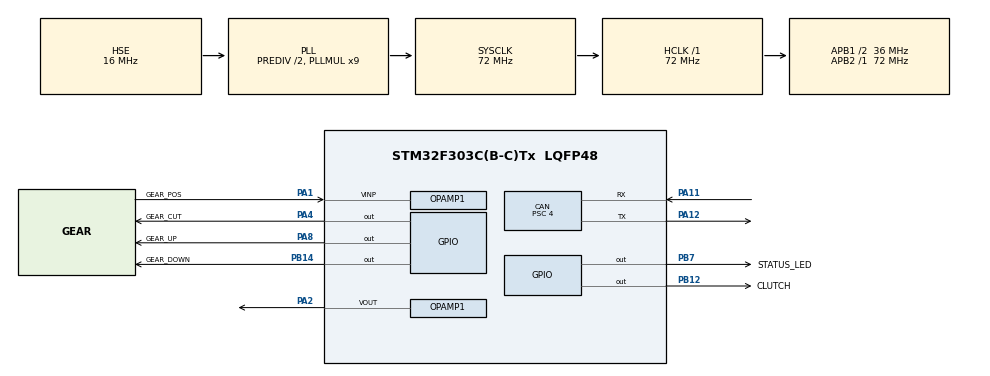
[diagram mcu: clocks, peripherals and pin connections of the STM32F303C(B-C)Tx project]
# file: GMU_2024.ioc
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ADC1.Channel-1\#ChannelRegularConversion=ADC_CHANNEL_3
ADC1.Channel-10\#ChannelRegularConversion=ADC_CHANNEL_3
ADC1.Channel-11\#ChannelRegularConversion=ADC_CHANNEL_3
ADC1.Channel-12\#ChannelRegularConversion=ADC_CHANNEL_3
ADC1.Channel-13\#ChannelRegularConversion=ADC_CHANNEL_3
ADC1.Channel-14\#ChannelRegularConversion=ADC_CHANNEL_3
ADC1.Channel-15\#ChannelRegularConversion=ADC_CHANNEL_3
ADC1.Channel-16\#ChannelRegularConversion=ADC_CHANNEL_3
ADC1.Channel-2\#ChannelRegularConversion=ADC_CHANNEL_3
ADC1.Channel-3\#ChannelRegularConversion=ADC_CHANNEL_3
ADC1.Channel-4\#ChannelRegularConversion=ADC_CHANNEL_3
ADC1.Channel-5\#ChannelRegularConversion=ADC_CHANNEL_3
ADC1.Channel-6\#ChannelRegularConversion=ADC_CHANNEL_3
ADC1.Channel-7\#ChannelRegularConversion=ADC_CHANNEL_3
ADC1.Channel-8\#ChannelRegularConversion=ADC_CHANNEL_3
ADC1.Channel-9\#ChannelRegularConversion=ADC_CHANNEL_3
ADC1.ClockPrescaler=ADC_CLOCK_SYNC_PCLK_DIV1
ADC1.ContinuousConvMode=ENABLE
ADC1.DMAContinuousRequests=ENABLE
ADC1.EnableInjectedConversion=DISABLE
ADC1.NbrOfConversion=16
ADC1.NbrOfConversionFlag=1
ADC1.Offset-1\#ChannelRegularConversion=0
ADC1.Offset-10\#ChannelRegularConversion=0
ADC1.Offset-11\#ChannelRegularConversion=0
ADC1.Offset-12\#ChannelRegularConversion=0
ADC1.Offset-13\#ChannelRegularConversion=0
ADC1.Offset-14\#ChannelRegularConversion=0
ADC1.Offset-15\#ChannelRegularConversion=0
ADC1.Offset-16\#ChannelRegularConversion=0
ADC1.Offset-2\#ChannelRegularConversion=0
ADC1.Offset-3\#ChannelRegularConversion=0
ADC1.Offset-4\#ChannelRegularConversion=0
ADC1.Offset-5\#ChannelRegularConversion=0
ADC1.Offset-6\#ChannelRegularConversion=0
ADC1.Offset-7\#ChannelRegularConversion=0
ADC1.Offset-8\#ChannelRegularConversion=0
ADC1.Offset-9\#ChannelRegularConversion=0
ADC1.OffsetNumber-1\#ChannelRegularConversion=ADC_OFFSET_NONE
ADC1.OffsetNumber-10\#ChannelRegularConversion=ADC_OFFSET_NONE
ADC1.OffsetNumber-11\#ChannelRegularConversion=ADC_OFFSET_NONE
ADC1.OffsetNumber-12\#ChannelRegularConversion=ADC_OFFSET_NONE
ADC1.OffsetNumber-13\#ChannelRegularConversion=ADC_OFFSET_NONE
ADC1.OffsetNumber-14\#ChannelRegularConversion=ADC_OFFSET_NONE
ADC1.OffsetNumber-15\#ChannelRegularConversion=ADC_OFFSET_NONE
ADC1.OffsetNumber-16\#ChannelRegularConversion=ADC_OFFSET_NONE
ADC1.OffsetNumber-2\#ChannelRegularConversion=ADC_OFFSET_NONE
ADC1.OffsetNumber-3\#ChannelRegularConversion=ADC_OFFSET_NONE
ADC1.OffsetNumber-4\#ChannelRegularConversion=ADC_OFFSET_NONE
ADC1.OffsetNumber-5\#ChannelRegularConversion=ADC_OFFSET_NONE
ADC1.OffsetNumber-6\#ChannelRegularConversion=ADC_OFFSET_NONE
ADC1.OffsetNumber-7\#ChannelRegularConversion=ADC_OFFSET_NONE
ADC1.OffsetNumber-8\#ChannelRegularConversion=ADC_OFFSET_NONE
ADC1.OffsetNumber-9\#ChannelRegularConversion=ADC_OFFSET_NONE
ADC1.Rank-1\#ChannelRegularConversion=1
ADC1.Rank-10\#ChannelRegularConversion=10
ADC1.Rank-11\#ChannelRegularConversion=11
ADC1.Rank-12\#ChannelRegularConversion=12
ADC1.Rank-13\#ChannelRegularConversion=13
ADC1.Rank-14\#ChannelRegularConversion=14
ADC1.Rank-15\#ChannelRegularConversion=15
ADC1.Rank-16\#ChannelRegularConversion=16
ADC1.Rank-2\#ChannelRegularConversion=2
ADC1.Rank-3\#ChannelRegularConversion=3
ADC1.Rank-4\#ChannelRegularConversion=4
ADC1.Rank-5\#ChannelRegularConversion=5
ADC1.Rank-6\#ChannelRegularConversion=6
ADC1.Rank-7\#ChannelRegularConversion=7
ADC1.Rank-8\#ChannelRegularConversion=8
ADC1.Rank-9\#ChannelRegularConversion=9
ADC1.SamplingTime-1\#ChannelRegularConversion=ADC_SAMPLETIME_61CYCLES_5
ADC1.SamplingTime-10\#ChannelRegularConversion=ADC_SAMPLETIME_61CYCLES_5
ADC1.SamplingTime-11\#ChannelRegularConversion=ADC_SAMPLETIME_61CYCLES_5
ADC1.SamplingTime-12\#ChannelRegularConversion=ADC_SAMPLETIME_61CYCLES_5
ADC1.SamplingTime-13\#ChannelRegularConversion=ADC_SAMPLETIME_61CYCLES_5
ADC1.SamplingTime-14\#ChannelRegularConversion=ADC_SAMPLETIME_61CYCLES_5
ADC1.SamplingTime-15\#ChannelRegularConversion=ADC_SAMPLETIME_61CYCLES_5
ADC1.SamplingTime-16\#ChannelRegularConversion=ADC_SAMPLETIME_61CYCLES_5
ADC1.SamplingTime-2\#ChannelRegularConversion=ADC_SAMPLETIME_61CYCLES_5
ADC1.SamplingTime-3\#ChannelRegularConversion=ADC_SAMPLETIME_61CYCLES_5
ADC1.SamplingTime-4\#ChannelRegularConversion=ADC_SAMPLETIME_61CYCLES_5
ADC1.SamplingTime-5\#ChannelRegularConversion=ADC_SAMPLETIME_61CYCLES_5
ADC1.SamplingTime-6\#ChannelRegularConversion=ADC_SAMPLETIME_61CYCLES_5
ADC1.SamplingTime-7\#ChannelRegularConversion=ADC_SAMPLETIME_61CYCLES_5
ADC1.SamplingTime-8\#ChannelRegularConversion=ADC_SAMPLETIME_61CYCLES_5
ADC1.SamplingTime-9\#ChannelRegularConversion=ADC_SAMPLETIME_61CYCLES_5
ADC1.SamplingTimeOPAMP-1\#ChannelRegularConversion=ADC_SAMPLETIME_61CYCLES_5
ADC1.SamplingTimeOPAMP-10\#ChannelRegularConversion=ADC_SAMPLETIME_61CYCLES_5
ADC1.SamplingTimeOPAMP-11\#ChannelRegularConversion=ADC_SAMPLETIME_61CYCLES_5
ADC1.SamplingTimeOPAMP-12\#ChannelRegularConversion=ADC_SAMPLETIME_61CYCLES_5
ADC1.SamplingTimeOPAMP-13\#ChannelRegularConversion=ADC_SAMPLETIME_61CYCLES_5
ADC1.SamplingTimeOPAMP-14\#ChannelRegularConversion=ADC_SAMPLETIME_61CYCLES_5
ADC1.SamplingTimeOPAMP-15\#ChannelRegularConversion=ADC_SAMPLETIME_61CYCLES_5
ADC1.SamplingTimeOPAMP-16\#ChannelRegularConversion=ADC_SAMPLETIME_61CYCLES_5
ADC1.SamplingTimeOPAMP-2\#ChannelRegularConversion=ADC_SAMPLETIME_61CYCLES_5
ADC1.SamplingTimeOPAMP-3\#ChannelRegularConversion=ADC_SAMPLETIME_61CYCLES_5
ADC1.SamplingTimeOPAMP-4\#ChannelRegularConversion=ADC_SAMPLETIME_61CYCLES_5
ADC1.SamplingTimeOPAMP-5\#ChannelRegularConversion=ADC_SAMPLETIME_61CYCLES_5
ADC1.SamplingTimeOPAMP-6\#ChannelRegularConversion=ADC_SAMPLETIME_61CYCLES_5
ADC1.SamplingTimeOPAMP-7\#ChannelRegularConversion=ADC_SAMPLETIME_61CYCLES_5
ADC1.SamplingTimeOPAMP-8\#ChannelRegularConversion=ADC_SAMPLETIME_61CYCLES_5
ADC1.SamplingTimeOPAMP-9\#ChannelRegularConversion=ADC_SAMPLETIME_61CYCLES_5
ADC1.master=1
CAN.ABOM=DISABLE
CAN.BS1=CAN_BS1_11TQ
CAN.BS2=CAN_BS2_6TQ
CAN.CalculateBaudRate=500000
CAN.CalculateTimeBit=2000
CAN.CalculateTimeQuantum=111.11111111111111
CAN.NART=DISABLE
CAN.Prescaler=4
Dma.ADC1.0.Direction=DMA_PERIPH_TO_MEMORY
Dma.ADC1.0.Instance=DMA1_Channel1
Dma.ADC1.0.MemDataAlignment=DMA_MDATAALIGN_HALFWORD
Dma.ADC1.0.MemInc=DMA_MINC_ENABLE
Dma.ADC1.0.Mode=DMA_CIRCULAR
Dma.ADC1.0.PeriphDataAlignment=DMA_PDATAALIGN_HALFWORD
Dma.ADC1.0.PeriphInc=DMA_PINC_DISABLE
Dma.ADC1.0.Priority=DMA_PRIORITY_VERY_HIGH
Dma.Request0=ADC1
Mcu.Family=STM32F3
Mcu.Name=STM32F303C(B-C)Tx
Mcu.Package=LQFP48
NVIC.ADC1_2_IRQn=true\:0\:0\:false\:false\:true\:true\:true\:true
NVIC.CAN_RX1_IRQn=true\:0\:0\:false\:false\:true\:true\:true\:true
NVIC.CAN_SCE_IRQn=true\:0\:0\:false\:false\:true\:true\:false\:true
NVIC.DMA1_Channel1_IRQn=true\:0\:0\:false\:false\:true\:false\:true\:true
NVIC.PriorityGroup=NVIC_PRIORITYGROUP_4
NVIC.TIM2_IRQn=true\:0\:0\:false\:false\:true\:true\:true\:true
NVIC.USB_HP_CAN_TX_IRQn=true\:0\:0\:false\:false\:true\:true\:true\:true
NVIC.USB_LP_CAN_RX0_IRQn=true\:0\:0\:false\:false\:true\:true\:true\:true
PA1.GPIO_Label=GEAR_POS
PA1.Mode=Follower
PA1.Signal=OPAMP1_VINP
PA11.Mode=CAN_Activate
PA11.Signal=CAN_RX
PA12.Mode=CAN_Activate
PA12.Signal=CAN_TX
PA13.Mode=Serial_Wire
PA13.Signal=SYS_JTMS-SWDIO
PA14.Mode=Serial_Wire
PA14.Signal=SYS_JTCK-SWCLK
PA2.Mode=Follower
PA2.Signal=OPAMP1_VOUT
PA4.GPIO_Label=GEAR_CUT
PA4.Signal=GPIO_Output
PA8.GPIO_Label=GEAR_UP
PA8.GPIO_Speed=GPIO_SPEED_FREQ_HIGH
PA8.Signal=GPIO_Output
PB12.GPIO_Label=CLUTCH
PB12.GPIO_Speed=GPIO_SPEED_FREQ_HIGH
PB12.Signal=GPIO_Output
PB14.GPIO_Label=GEAR_DOWN
PB14.GPIO_Speed=GPIO_SPEED_FREQ_HIGH
PB14.Signal=GPIO_Output
PB7.GPIO_Label=STATUS_LED
PB7.Signal=GPIO_Output
PF0-OSC_IN.Mode=HSE-External-Clock-Source
PF0-OSC_IN.Signal=RCC_OSC_IN
ProjectManager.HeapSize=0x200
ProjectManager.StackSize=0x400
ProjectManager.TargetToolchain=STM32CubeIDE
RCC.AHBFreq_Value=72000000
RCC.APB1CLKDivider=RCC_HCLK_DIV2
RCC.APB1Freq_Value=36000000
RCC.APB1TimFreq_Value=72000000
RCC.APB2Freq_Value=72000000
RCC.APB2TimFreq_Value=72000000
RCC.CortexFreq_Value=72000000
RCC.HCLKFreq_Value=72000000
RCC.HSE_VALUE=16000000
RCC.HSI_VALUE=8000000
RCC.LSE_VALUE=32768
RCC.PLLMUL=RCC_PLL_MUL9
RCC.PLLSourceVirtual=RCC_PLLSOURCE_HSE
RCC.RCC_PLLsource_Clock_Source_FROM_HSE=RCC_HSE_PREDIV_DIV2
RCC.SYSCLKFreq_VALUE=72000000
RCC.SYSCLKSourceVirtual=RCC_SYSCLKSOURCE_PLLCLK
RCC.USBFreq_Value=72000000
TIM2.Period=17999
TIM2.Prescaler=7199
VP_ADC1_OPAMP_OUT1.Mode=IN3-OPAMP1-Single-Ended
VP_TIM2_VS_ClockSourceINT.Mode=Internal
board=custom

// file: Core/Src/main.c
/* USER CODE BEGIN Header */
/**
  ******************************************************************************
  * @file           : main.c
  * @brief          : Main program body
  ******************************************************************************
  * @attention
  *
  * Copyright (c) 2024 STMicroelectronics.
  * All rights reserved.
  *
  * This software is licensed under terms that can be found in the LICENSE file
  * in the root directory of this software component.
  * If no LICENSE file comes with this software, it is provided AS-IS.
  *
  ******************************************************************************
  */
/* USER CODE END Header */
#include "main.h"
#include "adc.h"
#include "can.h"
#include "dma.h"
#include "opamp.h"
#include "tim.h"
#include "gpio.h"

void SystemClock_Config(void);

int main(void)
{

  /* MCU Configuration--------------------------------------------------------*/

  /* Reset of all peripherals, Initializes the Flash interface and the Systick. */
  HAL_Init();

  /* Configure the system clock */
  SystemClock_Config();

  /* Initialize all configured peripherals */
  MX_GPIO_Init();
  MX_DMA_Init();
  MX_CAN_Init();
  MX_OPAMP1_Init();
  MX_ADC1_Init();
  MX_TIM2_Init();
  /* USER CODE BEGIN 2 */
  AppInit();
  HAL_TIM_Base_Start_IT(&htim2);
  AppProcess();
  /* USER CODE END 2 */

  /* Infinite loop */
  while (1)
  {

  }
}

void SystemClock_Config(void)
{
  RCC_OscInitTypeDef RCC_OscInitStruct = {0};
  RCC_ClkInitTypeDef RCC_ClkInitStruct = {0};

  /** Initializes the RCC Oscillators according to the specified parameters
  * in the RCC_OscInitTypeDef structure.
  */
  RCC_OscInitStruct.OscillatorType = RCC_OSCILLATORTYPE_HSE;
  RCC_OscInitStruct.HSEState = RCC_HSE_BYPASS;
  RCC_OscInitStruct.HSEPredivValue = RCC_HSE_PREDIV_DIV2;
  RCC_OscInitStruct.HSIState = RCC_HSI_ON;
  RCC_OscInitStruct.PLL.PLLState = RCC_PLL_ON;
  RCC_OscInitStruct.PLL.PLLSource = RCC_PLLSOURCE_HSE;
  RCC_OscInitStruct.PLL.PLLMUL = RCC_PLL_MUL9;
  if (HAL_RCC_OscConfig(&RCC_OscInitStruct) != HAL_OK)
  {
    Error_Handler();
  }

  /** Initializes the CPU, AHB and APB buses clocks
  */
  RCC_ClkInitStruct.ClockType = RCC_CLOCKTYPE_HCLK|RCC_CLOCKTYPE_SYSCLK
                              |RCC_CLOCKTYPE_PCLK1|RCC_CLOCKTYPE_PCLK2;
  RCC_ClkInitStruct.SYSCLKSource = RCC_SYSCLKSOURCE_PLLCLK;
  RCC_ClkInitStruct.AHBCLKDivider = RCC_SYSCLK_DIV1;
  RCC_ClkInitStruct.APB1CLKDivider = RCC_HCLK_DIV2;
  RCC_ClkInitStruct.APB2CLKDivider = RCC_HCLK_DIV1;

  if (HAL_RCC_ClockConfig(&RCC_ClkInitStruct, FLASH_LATENCY_2) != HAL_OK)
  {
    Error_Handler();
  }
}

/* USER CODE BEGIN 4 */
void HAL_TIM_PeriodElapsedCallback(TIM_HandleTypeDef *htim)
{
	if(htim->Instance == TIM2)
	{
		HAL_GPIO_TogglePin(STATUS_LED_GPIO_Port, STATUS_LED_Pin);
	}
}
/* USER CODE END 4 */

void Error_Handler(void)
{
  __disable_irq();
  while (1)
  {
  }
}
